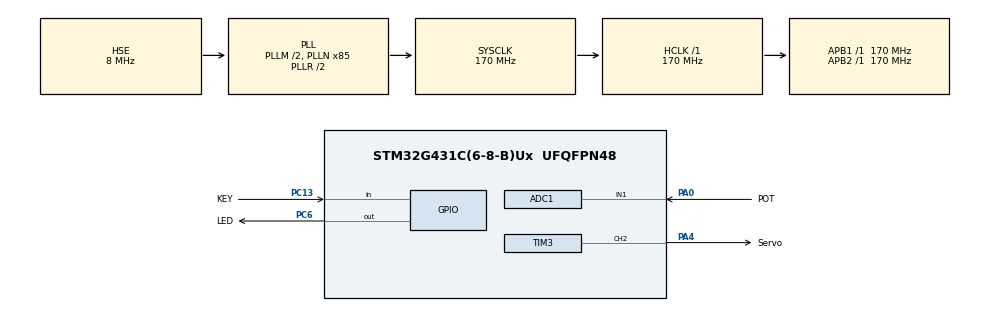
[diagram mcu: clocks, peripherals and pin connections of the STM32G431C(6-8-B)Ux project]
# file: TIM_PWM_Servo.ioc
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ADC1.Channel-0\#ChannelRegularConversion=ADC_CHANNEL_1
ADC1.NbrOfConversionFlag=1
ADC1.OffsetNumber-0\#ChannelRegularConversion=ADC_OFFSET_NONE
ADC1.Rank-0\#ChannelRegularConversion=1
ADC1.SamplingTime-0\#ChannelRegularConversion=ADC_SAMPLETIME_2CYCLES_5
ADC1.master=1
Mcu.Family=STM32G4
Mcu.Name=STM32G431C(6-8-B)Ux
Mcu.Package=UFQFPN48
NVIC.PriorityGroup=NVIC_PRIORITYGROUP_4
PA0.GPIO_Label=POT
PA0.Mode=IN1-Single-Ended
PA0.Signal=ADC1_IN1
PA13.Mode=Serial_Wire
PA13.Signal=SYS_JTMS-SWDIO
PA14.Mode=Serial_Wire
PA14.Signal=SYS_JTCK-SWCLK
PA4.GPIO_Label=Servo
PA4.Signal=S_TIM3_CH2
PC13.GPIO_Label=KEY
PC13.GPIO_PuPd=GPIO_PULLDOWN
PC13.Signal=GPIO_Input
PC6.GPIO_Label=LED
PC6.Signal=GPIO_Output
PF0-OSC_IN.Mode=HSE-External-Oscillator
PF0-OSC_IN.Signal=RCC_OSC_IN
PF1-OSC_OUT.Mode=HSE-External-Oscillator
PF1-OSC_OUT.Signal=RCC_OSC_OUT
ProjectManager.HeapSize=0x200
ProjectManager.StackSize=0x400
ProjectManager.TargetToolchain=STM32CubeIDE
RCC.ADC12Freq_Value=170000000
RCC.AHBFreq_Value=170000000
RCC.APB1Freq_Value=170000000
RCC.APB1TimFreq_Value=170000000
RCC.APB2Freq_Value=170000000
RCC.APB2TimFreq_Value=170000000
RCC.CortexFreq_Value=170000000
RCC.EXTERNAL_CLOCK_VALUE=12288000
RCC.HCLKFreq_Value=170000000
RCC.HSE_VALUE=8000000
RCC.HSI48_VALUE=48000000
RCC.HSI_VALUE=16000000
RCC.LSE_VALUE=32768
RCC.PLLM=RCC_PLLM_DIV2
RCC.PLLN=85
RCC.PLLSourceVirtual=RCC_PLLSOURCE_HSE
RCC.SYSCLKFreq_VALUE=170000000
RCC.SYSCLKSource=RCC_SYSCLKSOURCE_PLLCLK
RCC.USBFreq_Value=170000000
RCC.VCOOutputFreq_Value=340000000
SH.S_TIM3_CH2.0=TIM3_CH2,PWM Generation2 CH2
TIM3.Channel-PWM\ Generation2\ CH2=TIM_CHANNEL_2
TIM3.PeriodNoDither=20000
TIM3.Prescaler=170
VP_SYS_VS_DBSignals.Mode=DisableDeadBatterySignals
board=custom

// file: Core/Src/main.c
/* USER CODE BEGIN Header */
/**
  ******************************************************************************
  * @file           : main.c
  * @brief          : Main program body
  ******************************************************************************
  * @attention
  *
  * Copyright (c) 2025 STMicroelectronics.
  * All rights reserved.
  *
  * This software is licensed under terms that can be found in the LICENSE file
  * in the root directory of this software component.
  * If no LICENSE file comes with this software, it is provided AS-IS.
  *
  ******************************************************************************
  */
/* USER CODE END Header */
#include "main.h"

ADC_HandleTypeDef hadc1;

TIM_HandleTypeDef htim3;

void SystemClock_Config(void);
static void MX_GPIO_Init(void);
static void MX_TIM3_Init(void);
static void MX_ADC1_Init(void);

int main(void)
{

  /* MCU Configuration--------------------------------------------------------*/

  /* Reset of all peripherals, Initializes the Flash interface and the Systick. */
  HAL_Init();

  /* Configure the system clock */
  SystemClock_Config();

  /* Initialize all configured peripherals */
  MX_GPIO_Init();
  MX_TIM3_Init();
  MX_ADC1_Init();
  /* USER CODE BEGIN 2 */

  htim3.Instance->CCR2 = 1000;
  HAL_TIM_PWM_Start(&htim3, TIM_CHANNEL_2);

  /* USER CODE END 2 */

  /* Infinite loop */
  /* USER CODE BEGIN WHILE */
  while (1)
  {
	  if (HAL_GPIO_ReadPin(KEY_GPIO_Port, KEY_Pin) == GPIO_PIN_SET) {
		  if (htim3.Instance->CCR2 < 2000) {
			  htim3.Instance->CCR2++;
		  }
	  } else {
		  if (htim3.Instance->CCR2 > 1000) {
			  htim3.Instance->CCR2--;
		  }
	  }

	  HAL_Delay(1);
    /* USER CODE END WHILE */

  }
}

void SystemClock_Config(void)
{
  RCC_OscInitTypeDef RCC_OscInitStruct = {0};
  RCC_ClkInitTypeDef RCC_ClkInitStruct = {0};

  /** Configure the main internal regulator output voltage
  */
  HAL_PWREx_ControlVoltageScaling(PWR_REGULATOR_VOLTAGE_SCALE1_BOOST);

  /** Initializes the RCC Oscillators according to the specified parameters
  * in the RCC_OscInitTypeDef structure.
  */
  RCC_OscInitStruct.OscillatorType = RCC_OSCILLATORTYPE_HSE;
  RCC_OscInitStruct.HSEState = RCC_HSE_ON;
  RCC_OscInitStruct.PLL.PLLState = RCC_PLL_ON;
  RCC_OscInitStruct.PLL.PLLSource = RCC_PLLSOURCE_HSE;
  RCC_OscInitStruct.PLL.PLLM = RCC_PLLM_DIV2;
  RCC_OscInitStruct.PLL.PLLN = 85;
  RCC_OscInitStruct.PLL.PLLP = RCC_PLLP_DIV2;
  RCC_OscInitStruct.PLL.PLLQ = RCC_PLLQ_DIV2;
  RCC_OscInitStruct.PLL.PLLR = RCC_PLLR_DIV2;
  if (HAL_RCC_OscConfig(&RCC_OscInitStruct) != HAL_OK)
  {
    Error_Handler();
  }

  /** Initializes the CPU, AHB and APB buses clocks
  */
  RCC_ClkInitStruct.ClockType = RCC_CLOCKTYPE_HCLK|RCC_CLOCKTYPE_SYSCLK
                              |RCC_CLOCKTYPE_PCLK1|RCC_CLOCKTYPE_PCLK2;
  RCC_ClkInitStruct.SYSCLKSource = RCC_SYSCLKSOURCE_PLLCLK;
  RCC_ClkInitStruct.AHBCLKDivider = RCC_SYSCLK_DIV1;
  RCC_ClkInitStruct.APB1CLKDivider = RCC_HCLK_DIV1;
  RCC_ClkInitStruct.APB2CLKDivider = RCC_HCLK_DIV1;

  if (HAL_RCC_ClockConfig(&RCC_ClkInitStruct, FLASH_LATENCY_4) != HAL_OK)
  {
    Error_Handler();
  }
}

static void MX_ADC1_Init(void)
{

  ADC_MultiModeTypeDef multimode = {0};
  ADC_ChannelConfTypeDef sConfig = {0};

  /** Common config
  */
  hadc1.Instance = ADC1;
  hadc1.Init.ClockPrescaler = ADC_CLOCK_SYNC_PCLK_DIV4;
  hadc1.Init.Resolution = ADC_RESOLUTION_12B;
  hadc1.Init.DataAlign = ADC_DATAALIGN_RIGHT;
  hadc1.Init.GainCompensation = 0;
  hadc1.Init.ScanConvMode = ADC_SCAN_DISABLE;
  hadc1.Init.EOCSelection = ADC_EOC_SINGLE_CONV;
  hadc1.Init.LowPowerAutoWait = DISABLE;
  hadc1.Init.ContinuousConvMode = DISABLE;
  hadc1.Init.NbrOfConversion = 1;
  hadc1.Init.DiscontinuousConvMode = DISABLE;
  hadc1.Init.ExternalTrigConv = ADC_SOFTWARE_START;
  hadc1.Init.ExternalTrigConvEdge = ADC_EXTERNALTRIGCONVEDGE_NONE;
  hadc1.Init.DMAContinuousRequests = DISABLE;
  hadc1.Init.Overrun = ADC_OVR_DATA_PRESERVED;
  hadc1.Init.OversamplingMode = DISABLE;
  if (HAL_ADC_Init(&hadc1) != HAL_OK)
  {
    Error_Handler();
  }

  /** Configure the ADC multi-mode
  */
  multimode.Mode = ADC_MODE_INDEPENDENT;
  if (HAL_ADCEx_MultiModeConfigChannel(&hadc1, &multimode) != HAL_OK)
  {
    Error_Handler();
  }

  /** Configure Regular Channel
  */
  sConfig.Channel = ADC_CHANNEL_1;
  sConfig.Rank = ADC_REGULAR_RANK_1;
  sConfig.SamplingTime = ADC_SAMPLETIME_2CYCLES_5;
  sConfig.SingleDiff = ADC_SINGLE_ENDED;
  sConfig.OffsetNumber = ADC_OFFSET_NONE;
  sConfig.Offset = 0;
  if (HAL_ADC_ConfigChannel(&hadc1, &sConfig) != HAL_OK)
  {
    Error_Handler();
  }

}

static void MX_TIM3_Init(void)
{

  TIM_MasterConfigTypeDef sMasterConfig = {0};
  TIM_OC_InitTypeDef sConfigOC = {0};

  htim3.Instance = TIM3;
  htim3.Init.Prescaler = 170;
  htim3.Init.CounterMode = TIM_COUNTERMODE_UP;
  htim3.Init.Period = 20000;
  htim3.Init.ClockDivision = TIM_CLOCKDIVISION_DIV1;
  htim3.Init.AutoReloadPreload = TIM_AUTORELOAD_PRELOAD_DISABLE;
  if (HAL_TIM_PWM_Init(&htim3) != HAL_OK)
  {
    Error_Handler();
  }
  sMasterConfig.MasterOutputTrigger = TIM_TRGO_RESET;
  sMasterConfig.MasterSlaveMode = TIM_MASTERSLAVEMODE_DISABLE;
  if (HAL_TIMEx_MasterConfigSynchronization(&htim3, &sMasterConfig) != HAL_OK)
  {
    Error_Handler();
  }
  sConfigOC.OCMode = TIM_OCMODE_PWM1;
  sConfigOC.Pulse = 0;
  sConfigOC.OCPolarity = TIM_OCPOLARITY_HIGH;
  sConfigOC.OCFastMode = TIM_OCFAST_DISABLE;
  if (HAL_TIM_PWM_ConfigChannel(&htim3, &sConfigOC, TIM_CHANNEL_2) != HAL_OK)
  {
    Error_Handler();
  }
  HAL_TIM_MspPostInit(&htim3);

}

static void MX_GPIO_Init(void)
{
  GPIO_InitTypeDef GPIO_InitStruct = {0};

  /* GPIO Ports Clock Enable */
  __HAL_RCC_GPIOC_CLK_ENABLE();
  __HAL_RCC_GPIOF_CLK_ENABLE();
  __HAL_RCC_GPIOA_CLK_ENABLE();

  /*Configure GPIO pin Output Level */
  HAL_GPIO_WritePin(LED_GPIO_Port, LED_Pin, GPIO_PIN_RESET);

  /*Configure GPIO pin : KEY_Pin */
  GPIO_InitStruct.Pin = KEY_Pin;
  GPIO_InitStruct.Mode = GPIO_MODE_INPUT;
  GPIO_InitStruct.Pull = GPIO_PULLDOWN;
  HAL_GPIO_Init(KEY_GPIO_Port, &GPIO_InitStruct);

  /*Configure GPIO pin : LED_Pin */
  GPIO_InitStruct.Pin = LED_Pin;
  GPIO_InitStruct.Mode = GPIO_MODE_OUTPUT_PP;
  GPIO_InitStruct.Pull = GPIO_NOPULL;
  GPIO_InitStruct.Speed = GPIO_SPEED_FREQ_LOW;
  HAL_GPIO_Init(LED_GPIO_Port, &GPIO_InitStruct);

}

void Error_Handler(void)
{
  __disable_irq();
  while (1)
  {
  }
}
